# MIMXRT1015 register map
Vendor: nxp.com; File version: 1.0
CPU: CM7 r0p1, little endian, MPU, FPU, VTOR, 4 interrupt priority bits
Registers are 32-bit, read-write, reset 0x0 unless marked. A register's access mark holds for its fields unless they carry their own. Offsets are from the block's base; [hi:lo] are bit positions; {n}, {i} and the like mark numbered series.

## TRNG
Base 0x400CC000
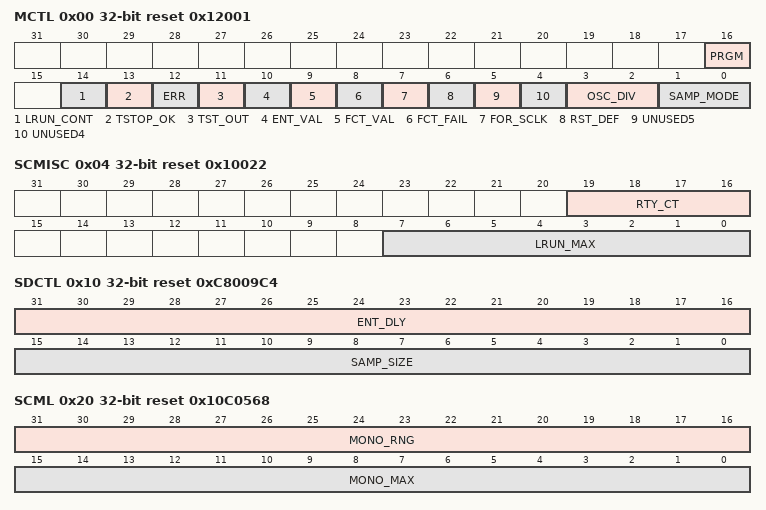
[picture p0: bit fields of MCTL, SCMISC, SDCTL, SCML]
0x00 MCTL reset 0x12001 — Miscellaneous Control Register
  [16] PRGM — Programming Mode Select
  [14] LRUN_CONT — Long run count continues between entropy generations
  [13] TSTOP_OK ro — TRNG_OK_TO_STOP
  [12] ERR write-1-clears — Read: Error status
  [11] TST_OUT ro — Read only: Test point inside ring oscillator.
  [10] ENT_VAL ro — Read only: Entropy Valid
  [9] FCT_VAL ro — Read only: Frequency Count Valid. Indicates that a valid frequency count may be read from FRQCNT.
  [8] FCT_FAIL ro — Read only: Frequency Count Fail
  [7] FOR_SCLK — Force System Clock
  [6] RST_DEF wo — Reset Defaults
  [5] UNUSED5 ro — This bit is unused. Always reads zero.
  [4] UNUSED4 ro — This bit is unused. Always reads zero.
  [3:2] OSC_DIV — Oscillator Divide
    0=OSC_DIV_DIV1 (use ring oscillator with no divide); 1=OSC_DIV_DIV2 (use ring oscillator divided-by-2); 2=OSC_DIV_DIV4 (use ring oscillator divided-by-4); 3=OSC_DIV_DIV8 (use ring oscillator divided-by-8)
  [1:0] SAMP_MODE — Sample Mode
    0=SAMP_MODE_VON_BOTH (use Von Neumann data into both Entropy shifter and Statistical Checker); 1=SAMP_MODE_RAW_BOTH (use raw data into both Entropy shifter and Statistical Checker); 2=SAMP_MODE_VON_ENT (use Von Neumann data into Entropy shifter. Use raw data into Statistical Checker); 3=SAMP_MODE_UNDEF (undefined/reserved.)
0x04 SCMISC reset 0x10022 — Statistical Check Miscellaneous Register
  [19:16] RTY_CT — RETRY COUNT
  [7:0] LRUN_MAX — LONG RUN MAX LIMIT
0x08 PKRRNG reset 0x9A3 — Poker Range Register
  [15:0] PKR_RNG — Poker Range
0x0C PKRMAX reset 0x6920 (MAX_SQ view) — Poker Maximum Limit Register
  [23:0] PKR_MAX — Poker Maximum Limit.
0x0C PKRSQ ro (MAX_SQ view) — Poker Square Calculation Result Register
  [23:0] PKR_SQ — Poker Square Calculation Result.
0x10 SDCTL reset 0xC8009C4 — Seed Control Register
  [31:16] ENT_DLY — Entropy Delay
  [15:0] SAMP_SIZE — Sample Size
0x14 SBLIM reset 0x3F (SBLIM_TOTSAM view) — Sparse Bit Limit Register
  [9:0] SB_LIM — Sparse Bit Limit
0x14 TOTSAM ro (SBLIM_TOTSAM view) — Total Samples Register
  [19:0] TOT_SAM — Total Samples
0x18 FRQMIN reset 0x640 — Frequency Count Minimum Limit Register
  [21:0] FRQ_MIN — Frequency Count Minimum Limit
0x1C FRQCNT ro (MAX_CNT view) — Frequency Count Register
  [21:0] FRQ_CT — Frequency Count
0x1C FRQMAX reset 0x6400 (MAX_CNT view) — Frequency Count Maximum Limit Register
  [21:0] FRQ_MAX — Frequency Counter Maximum Limit
0x20 SCMC ro (SCML_MC view) — Statistical Check Monobit Count Register
  [15:0] MONO_CT — Monobit Count
0x20 SCML reset 0x10C0568 (SCML_MC view) — Statistical Check Monobit Limit Register
  [31:16] MONO_RNG — Monobit Range
  [15:0] MONO_MAX — Monobit Maximum Limit
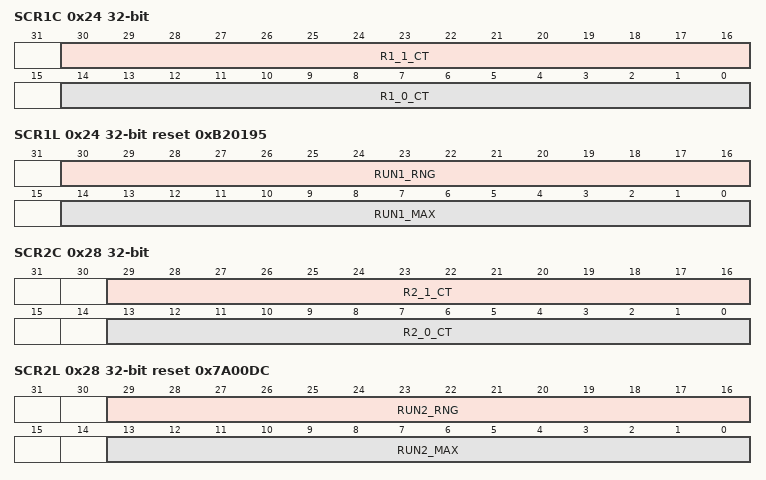
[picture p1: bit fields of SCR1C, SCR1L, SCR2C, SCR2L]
0x24 SCR1C ro (SCR1L_1C view) — Statistical Check Run Length 1 Count Register
  [30:16] R1_1_CT — Runs of One, Length 1 Count
  [14:0] R1_0_CT — Runs of Zero, Length 1 Count
0x24 SCR1L reset 0xB20195 (SCR1L_1C view) — Statistical Check Run Length 1 Limit Register
  [30:16] RUN1_RNG — Run Length 1 Range
  [14:0] RUN1_MAX — Run Length 1 Maximum Limit
0x28 SCR2C ro (SCR2L_2C view) — Statistical Check Run Length 2 Count Register
  [29:16] R2_1_CT — Runs of One, Length 2 Count
  [13:0] R2_0_CT — Runs of Zero, Length 2 Count
0x28 SCR2L reset 0x7A00DC (SCR2L_2C view) — Statistical Check Run Length 2 Limit Register
  [29:16] RUN2_RNG — Run Length 2 Range
  [13:0] RUN2_MAX — Run Length 2 Maximum Limit
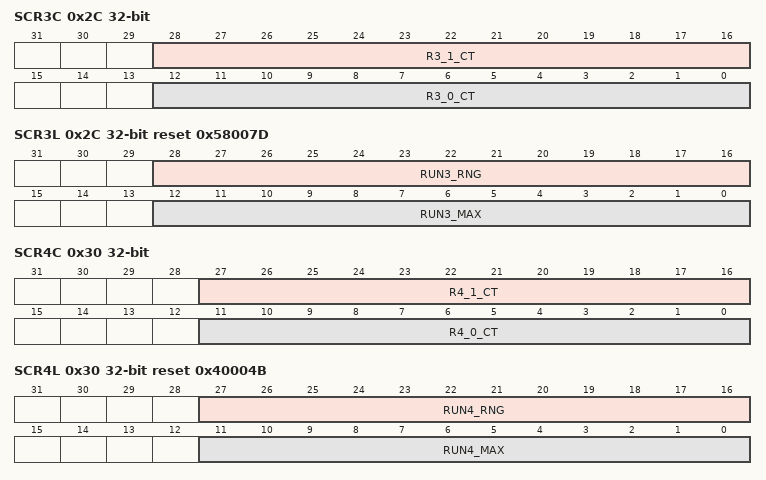
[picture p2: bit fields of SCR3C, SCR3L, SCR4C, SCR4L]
0x2C SCR3C ro (SCR3L_3C view) — Statistical Check Run Length 3 Count Register
  [28:16] R3_1_CT — Runs of Ones, Length 3 Count
  [12:0] R3_0_CT — Runs of Zeroes, Length 3 Count
0x2C SCR3L reset 0x58007D (SCR3L_3C view) — Statistical Check Run Length 3 Limit Register
  [28:16] RUN3_RNG — Run Length 3 Range
  [12:0] RUN3_MAX — Run Length 3 Maximum Limit
0x30 SCR4C ro (SCR4L_4C view) — Statistical Check Run Length 4 Count Register
  [27:16] R4_1_CT — Runs of One, Length 4 Count
  [11:0] R4_0_CT — Runs of Zero, Length 4 Count
0x30 SCR4L reset 0x40004B (SCR4L_4C view) — Statistical Check Run Length 4 Limit Register
  [27:16] RUN4_RNG — Run Length 4 Range
  [11:0] RUN4_MAX — Run Length 4 Maximum Limit
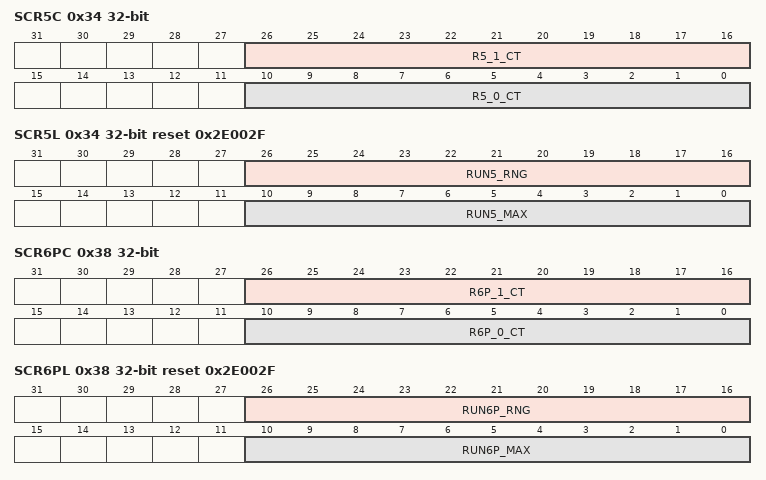
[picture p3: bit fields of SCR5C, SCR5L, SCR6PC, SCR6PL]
0x34 SCR5C ro (SCR5L_5C view) — Statistical Check Run Length 5 Count Register
  [26:16] R5_1_CT — Runs of One, Length 5 Count
  [10:0] R5_0_CT — Runs of Zero, Length 5 Count
0x34 SCR5L reset 0x2E002F (SCR5L_5C view) — Statistical Check Run Length 5 Limit Register
  [26:16] RUN5_RNG — Run Length 5 Range
  [10:0] RUN5_MAX — Run Length 5 Maximum Limit
0x38 SCR6PC ro (SCR6PL_PC view) — Statistical Check Run Length 6+ Count Register
  [26:16] R6P_1_CT — Runs of One, Length 6+ Count
  [10:0] R6P_0_CT — Runs of Zero, Length 6+ Count
0x38 SCR6PL reset 0x2E002F (SCR6PL_PC view) — Statistical Check Run Length 6+ Limit Register
  [26:16] RUN6P_RNG — Run Length 6+ Range
  [10:0] RUN6P_MAX — Run Length 6+ Maximum Limit
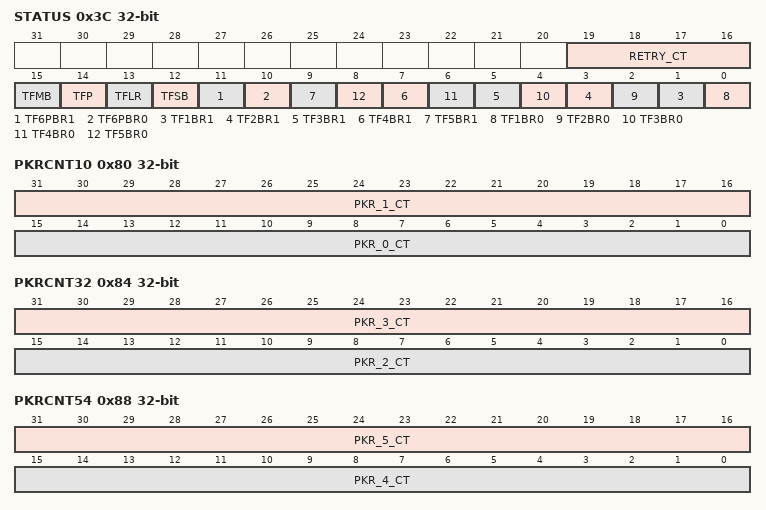
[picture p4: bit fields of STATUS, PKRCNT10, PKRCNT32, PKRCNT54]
0x3C STATUS ro
  [19:16] RETRY_CT — RETRY COUNT
  [15] TFMB — Test Fail, Mono Bit. If TFMB=1, the Mono Bit Test has failed.
  [14] TFP — Test Fail, Poker. If TFP=1, the Poker Test has failed.
  [13] TFLR — Test Fail, Long Run. If TFLR=1, the Long Run Test has failed.
  [12] TFSB — Test Fail, Sparse Bit. If TFSB=1, the Sparse Bit Test has failed.
  [11] TF6PBR1 — Test Fail, 6 Plus Bit Run, Sampling 1s
  [10] TF6PBR0 — Test Fail, 6 Plus Bit Run, Sampling 0s
  [2n-1] TF{n}BR1 (n=1..5) — Test Fail, {n}-Bit Run, Sampling 1s. If TF{n}BR1=1, the {n}-Bit Run, Sampling 1s Test has failed.
  [2n-2] TF{n}BR0 (n=1..5) — Test Fail, {n}-Bit Run, Sampling 0s. If TF{n}BR0=1, the {n}-Bit Run, Sampling 0s Test has failed.
{0x40+4i} ENT[{i}] (i=0..15) ro — Entropy Read Register
  [31:0] ENT — Entropy Value
0x80 PKRCNT10 ro — Statistical Check Poker Count 1 and 0 Register
  [31:16] PKR_1_CT — Poker 1h Count
  [15:0] PKR_0_CT — Poker 0h Count
0x84 PKRCNT32 ro — Statistical Check Poker Count 3 and 2 Register
  [31:16] PKR_3_CT — Poker 3h Count
  [15:0] PKR_2_CT — Poker 2h Count
0x88 PKRCNT54 ro — Statistical Check Poker Count 5 and 4 Register
  [31:16] PKR_5_CT — Poker 5h Count
  [15:0] PKR_4_CT — Poker 4h Count
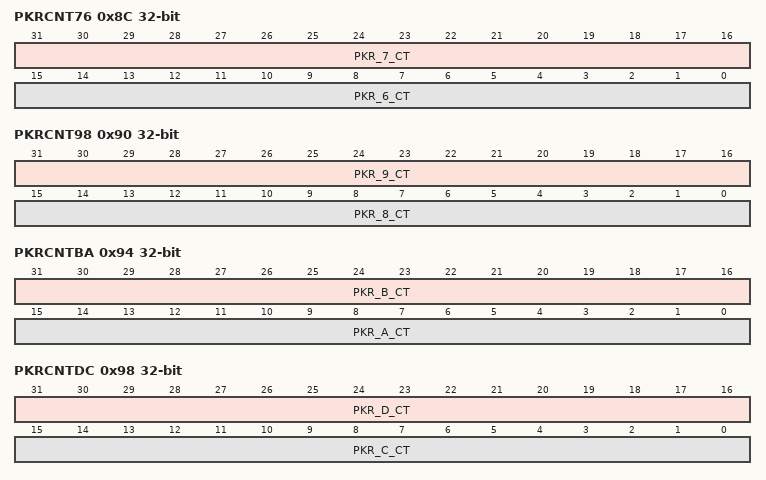
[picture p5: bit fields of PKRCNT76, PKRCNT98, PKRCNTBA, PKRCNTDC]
0x8C PKRCNT76 ro — Statistical Check Poker Count 7 and 6 Register
  [31:16] PKR_7_CT — Poker 7h Count
  [15:0] PKR_6_CT — Poker 6h Count
0x90 PKRCNT98 ro — Statistical Check Poker Count 9 and 8 Register
  [31:16] PKR_9_CT — Poker 9h Count
  [15:0] PKR_8_CT — Poker 8h Count
0x94 PKRCNTBA ro — Statistical Check Poker Count B and A Register
  [31:16] PKR_B_CT — Poker Bh Count
  [15:0] PKR_A_CT — Poker Ah Count
0x98 PKRCNTDC ro — Statistical Check Poker Count D and C Register
  [31:16] PKR_D_CT — Poker Dh Count
  [15:0] PKR_C_CT — Poker Ch Count
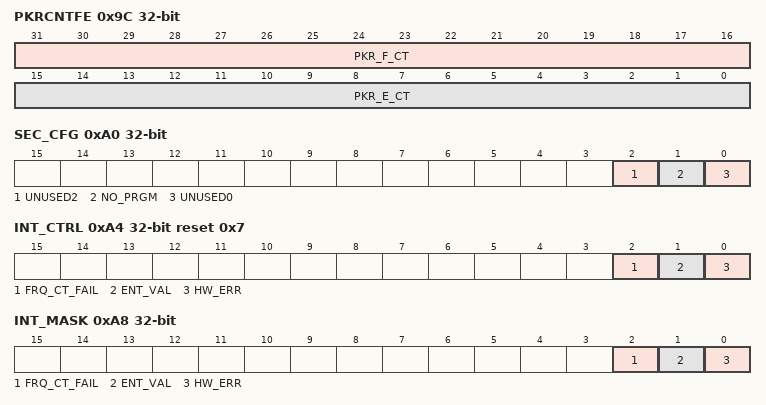
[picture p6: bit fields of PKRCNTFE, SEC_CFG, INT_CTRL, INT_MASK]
0x9C PKRCNTFE ro — Statistical Check Poker Count F and E Register
  [31:16] PKR_F_CT — Poker Fh Count
  [15:0] PKR_E_CT — Poker Eh Count
0xA0 SEC_CFG — Security Configuration Register
  [2] UNUSED2 — This bit is unused. Ignore.
  [1] NO_PRGM — If set, the TRNG registers cannot be programmed
    0=NO_PRGM_OFF (Programability of registers controlled only by the Miscellaneous Control Register's access mode bit.); 1=NO_PRGM_ON (Overides Miscellaneous Control Register access mode and prevents TRNG register programming.)
  [0] UNUSED0 — This bit is unused. Ignore.
0xA4 INT_CTRL reset 0x7 — Interrupt Control Register
  [2] FRQ_CT_FAIL — Same behavior as bit 0 of this register.
    0=FRQ_CT_FAIL_CLEAR (Same behavior as bit 0 of this register.); 1=FRQ_CT_FAIL_ON (Same behavior as bit 0 of this register.)
  [1] ENT_VAL — Same behavior as bit 0 of this register.
    0=ENT_VAL_CLEAR (Same behavior as bit 0 of this register.); 1=ENT_VAL_ON (Same behavior as bit 0 of this register.)
  [0] HW_ERR — Bit position that can be cleared if corresponding bit of INT_STATUS register has been asserted.
    0=HW_ERR_CLEAR (Corresponding bit of INT_STATUS register cleared.); 1=HW_ERR_ON (Corresponding bit of INT_STATUS register active.)
0xA8 INT_MASK — Mask Register
  [2] FRQ_CT_FAIL — Same behavior as bit 0 of this register.
    0=FRQ_CT_FAIL_MASKED (Same behavior as bit 0 of this register.); 1=FRQ_CT_FAIL_ACTIVE (Same behavior as bit 0 of this register.)
  [1] ENT_VAL — Same behavior as bit 0 of this register.
    0=ENT_VAL_MASKED (Same behavior as bit 0 of this register.); 1=ENT_VAL_ACTIVE (Same behavior as bit 0 of this register.)
  [0] HW_ERR — Bit position that can be cleared or set to enable the corresponding bit of INT_STATUS to show interupt status
    0=HW_ERR_MASKED (Corresponding interrupt of INT_STATUS is masked.); 1=HW_ERR_ACTIVE (Corresponding bit of INT_STATUS is active.)
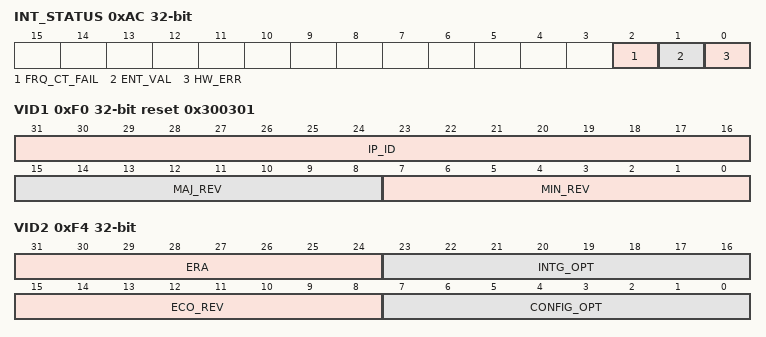
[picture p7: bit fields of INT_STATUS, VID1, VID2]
0xAC INT_STATUS ro — Interrupt Status Register
  [2] FRQ_CT_FAIL — Read only: Frequency Count Fail
    0=FRQ_CT_FAIL_NO_ERR (No hardware nor self test frequency errors.); 1=FRQ_CT_FAIL_ERR (The frequency counter has detected a failure.)
  [1] ENT_VAL — Read only: Entropy Valid
    0=ENT_VAL_INVALID (Busy generation entropy. Any value read is invalid.); 1=ENT_VAL_VALID (TRNG can be stopped and entropy is valid if read.)
  [0] HW_ERR — Read: Error status
    0=HW_ERR_NO (no error); 1=HW_ERR_YES (error detected.)
0xF0 VID1 ro reset 0x300301 — Version ID Register (MS)
  [31:16] IP_ID — Shows the IP ID.
    48=IP_ID_VAL (ID for TRNG.)
  [15:8] MAJ_REV — Shows the IP's Major revision of the TRNG.
    1=MAJ_REV_VAL (Major revision number for TRNG.)
  [7:0] MIN_REV — Shows the IP's Minor revision of the TRNG.
    0=MIN_REV_VAL (Minor revision number for TRNG.)
0xF4 VID2 ro — Version ID Register (LS)
  [31:24] ERA — Shows the compile options for the TRNG.
    0=ERA_VAL (COMPILE_OPT for TRNG.)
  [23:16] INTG_OPT — Shows the integration options for the TRNG
    0=INTG_OPT_VAL (INTG_OPT for TRNG.)
  [15:8] ECO_REV — Shows the IP's ECO revision of the TRNG.
    0=ECO_REV_VAL (TRNG_ECO_REV for TRNG.)
  [7:0] CONFIG_OPT — Shows the IP's Configuaration options for the TRNG.
    0=CONFIG_OPT_VAL (TRNG_CONFIG_OPT for TRNG.)
